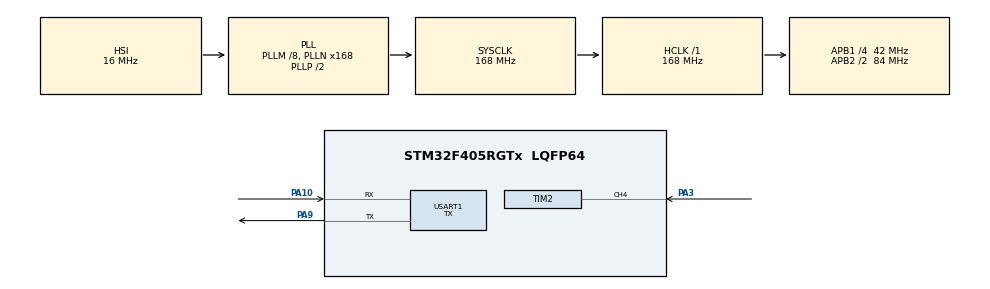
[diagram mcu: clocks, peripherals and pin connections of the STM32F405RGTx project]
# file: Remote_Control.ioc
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Dma.Request0=TIM2_CH2/CH4
Dma.TIM2_CH2/CH4.0.Direction=DMA_PERIPH_TO_MEMORY
Dma.TIM2_CH2/CH4.0.FIFOMode=DMA_FIFOMODE_DISABLE
Dma.TIM2_CH2/CH4.0.Instance=DMA1_Stream6
Dma.TIM2_CH2/CH4.0.MemDataAlignment=DMA_MDATAALIGN_WORD
Dma.TIM2_CH2/CH4.0.MemInc=DMA_MINC_ENABLE
Dma.TIM2_CH2/CH4.0.Mode=DMA_CIRCULAR
Dma.TIM2_CH2/CH4.0.PeriphDataAlignment=DMA_PDATAALIGN_WORD
Dma.TIM2_CH2/CH4.0.PeriphInc=DMA_PINC_DISABLE
Dma.TIM2_CH2/CH4.0.Priority=DMA_PRIORITY_LOW
Mcu.Family=STM32F4
Mcu.Name=STM32F405RGTx
Mcu.Package=LQFP64
NVIC.DMA1_Stream6_IRQn=true\:0\:0\:false\:false\:true\:false\:true\:true
NVIC.PriorityGroup=NVIC_PRIORITYGROUP_4
NVIC.TIM2_IRQn=true\:0\:0\:false\:false\:true\:true\:true\:true
PA10.Mode=Asynchronous
PA10.Signal=USART1_RX
PA13.Mode=Serial_Wire
PA13.Signal=SYS_JTMS-SWDIO
PA14.Mode=Serial_Wire
PA14.Signal=SYS_JTCK-SWCLK
PA3.Signal=S_TIM2_CH4
PA9.Mode=Asynchronous
PA9.Signal=USART1_TX
PH0-OSC_IN.Mode=HSE-External-Oscillator
PH0-OSC_IN.Signal=RCC_OSC_IN
PH1-OSC_OUT.Mode=HSE-External-Oscillator
PH1-OSC_OUT.Signal=RCC_OSC_OUT
ProjectManager.HeapSize=0x200
ProjectManager.StackSize=0x400
ProjectManager.TargetToolchain=STM32CubeIDE
RCC.48MHZClocksFreq_Value=84000000
RCC.AHBFreq_Value=168000000
RCC.APB1CLKDivider=RCC_HCLK_DIV4
RCC.APB1Freq_Value=42000000
RCC.APB1TimFreq_Value=84000000
RCC.APB2CLKDivider=RCC_HCLK_DIV2
RCC.APB2Freq_Value=84000000
RCC.APB2TimFreq_Value=168000000
RCC.CortexFreq_Value=168000000
RCC.HCLKFreq_Value=168000000
RCC.HSE_VALUE=8000000
RCC.HSI_VALUE=16000000
RCC.LSE_VALUE=32768
RCC.PLLM=8
RCC.PLLN=168
RCC.SYSCLKFreq_VALUE=168000000
RCC.SYSCLKSource=RCC_SYSCLKSOURCE_PLLCLK
RCC.VCOOutputFreq_Value=336000000
SH.S_TIM2_CH4.0=TIM2_CH4,Input_Capture4_from_TI4
TIM2.AutoReloadPreload=TIM_AUTORELOAD_PRELOAD_ENABLE
TIM2.Channel-Input_Capture4_from_TI4=TIM_CHANNEL_4
TIM2.ICPolarity_CH4=TIM_INPUTCHANNELPOLARITY_BOTHEDGE
TIM2.Period=0xFFFFFFFF
TIM2.Prescaler=167
USART1.Mode=MODE_TX
USART1.VirtualMode=VM_ASYNC
VP_TIM2_VS_ClockSourceINT.Mode=Internal
board=custom

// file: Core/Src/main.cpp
/* USER CODE BEGIN Header */
/**
  ******************************************************************************
  * @file           : main.c
  * @brief          : Main program body
  ******************************************************************************
  * @attention
  *
  * Copyright (c) 2025 STMicroelectronics.
  * All rights reserved.
  *
  * This software is licensed under terms that can be found in the LICENSE file
  * in the root directory of this software component.
  * If no LICENSE file comes with this software, it is provided AS-IS.
  *
  ******************************************************************************
  */
/* USER CODE END Header */
#include "main.h"
#include "dma.h"
#include "tim.h"
#include "usart.h"
#include "gpio.h"

/* USER CODE BEGIN Includes */
#include "HS1527Decoder.h"
/* USER CODE END Includes */

void SystemClock_Config(void);

/* USER CODE BEGIN 0 */
HS1527Decoder  hs1527decoder(&htim2, &huart1);
/* USER CODE END 0 */

int main(void)
{

  /* MCU Configuration--------------------------------------------------------*/

  /* Reset of all peripherals, Initializes the Flash interface and the Systick. */
  HAL_Init();

  /* Configure the system clock */
  SystemClock_Config();

  /* Initialize all configured peripherals */
  MX_GPIO_Init();
  MX_DMA_Init();
  MX_TIM2_Init();
  MX_USART1_UART_Init();
  /* USER CODE BEGIN 2 */
  hs1527decoder.begin();
  /* USER CODE END 2 */

  /* Infinite loop */
  while (1)
  {

  }
}

void SystemClock_Config(void)
{
  RCC_OscInitTypeDef RCC_OscInitStruct = {0};
  RCC_ClkInitTypeDef RCC_ClkInitStruct = {0};

  /** Configure the main internal regulator output voltage
  */
  __HAL_RCC_PWR_CLK_ENABLE();
  __HAL_PWR_VOLTAGESCALING_CONFIG(PWR_REGULATOR_VOLTAGE_SCALE1);

  /** Initializes the RCC Oscillators according to the specified parameters
  * in the RCC_OscInitTypeDef structure.
  */
  RCC_OscInitStruct.OscillatorType = RCC_OSCILLATORTYPE_HSI;
  RCC_OscInitStruct.HSIState = RCC_HSI_ON;
  RCC_OscInitStruct.HSICalibrationValue = RCC_HSICALIBRATION_DEFAULT;
  RCC_OscInitStruct.PLL.PLLState = RCC_PLL_ON;
  RCC_OscInitStruct.PLL.PLLSource = RCC_PLLSOURCE_HSI;
  RCC_OscInitStruct.PLL.PLLM = 8;
  RCC_OscInitStruct.PLL.PLLN = 168;
  RCC_OscInitStruct.PLL.PLLP = RCC_PLLP_DIV2;
  RCC_OscInitStruct.PLL.PLLQ = 4;
  if (HAL_RCC_OscConfig(&RCC_OscInitStruct) != HAL_OK)
  {
    Error_Handler();
  }

  /** Initializes the CPU, AHB and APB buses clocks
  */
  RCC_ClkInitStruct.ClockType = RCC_CLOCKTYPE_HCLK|RCC_CLOCKTYPE_SYSCLK
                              |RCC_CLOCKTYPE_PCLK1|RCC_CLOCKTYPE_PCLK2;
  RCC_ClkInitStruct.SYSCLKSource = RCC_SYSCLKSOURCE_PLLCLK;
  RCC_ClkInitStruct.AHBCLKDivider = RCC_SYSCLK_DIV1;
  RCC_ClkInitStruct.APB1CLKDivider = RCC_HCLK_DIV4;
  RCC_ClkInitStruct.APB2CLKDivider = RCC_HCLK_DIV2;

  if (HAL_RCC_ClockConfig(&RCC_ClkInitStruct, FLASH_LATENCY_5) != HAL_OK)
  {
    Error_Handler();
  }
}

/* USER CODE BEGIN 4 */
void HAL_TIM_IC_CaptureCallback(TIM_HandleTypeDef *htim) {
    if (htim == &htim2) {
        // считываем текущее значение таймера
        uint32_t timestamp = HAL_TIM_ReadCapturedValue(htim, TIM_CHANNEL_4);

        // передаем фронт в объект декодера
        hs1527decoder.processFront(timestamp);
    }
}
/* USER CODE END 4 */

void Error_Handler(void)
{
  __disable_irq();
  while (1)
  {
  }
}
